# NPCX498S register map
File version: 1.0
Registers are 8-bit, read-write, reset 0x0 unless marked. A register's access mark holds for its fields unless they carry their own. Offsets are from the block's base; [hi:lo] are bit positions; {n}, {i} and the like mark numbered series; 'fields as' and 'values as' point back to an identical list.

## FLM
Base 0x400F8000
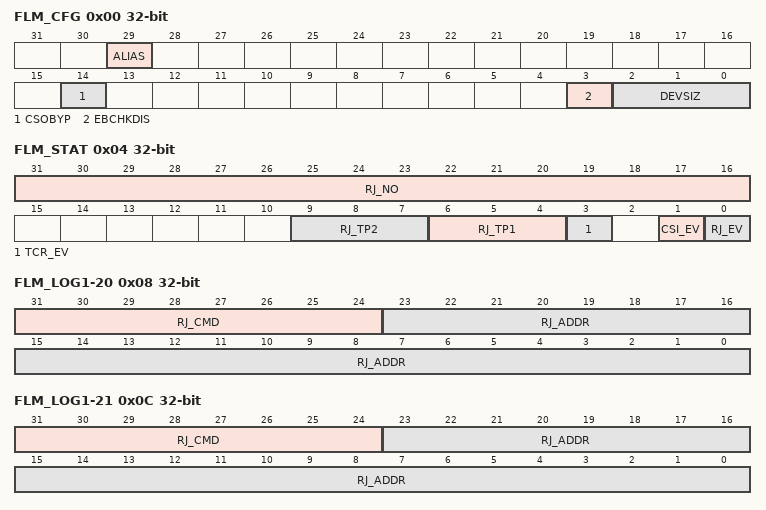
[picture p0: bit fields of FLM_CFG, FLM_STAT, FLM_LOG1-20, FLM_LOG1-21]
0x00 FLM_CFG 32-bit (reset mask 0xFF) — FLM Configuration Register (FLM_CFG)
  [29] ALIAS — Alias Flash Access Above Range
  [14] CSOBYP — FLM_CSIO Cut-Off Bypass
  [3] EBCHKDIS — Extra Bits Check Disable
  [2:0] DEVSIZ — Device Size
0x04 FLM_STAT 32-bit (reset mask 0xFF) — FLM Status Register (FLM_STAT)
  [31:16] RJ_NO — Rejection Number
  [9:7] RJ_TP2 — Rejection Type 2
  [6:4] RJ_TP1 — Rejection Type 1
  [3] TCR_EV — Transaction Counter Event
  [1] CSI_EV — Chip-Select Active Low Event
  [0] RJ_EV — Rejection Event
0x08 FLM_LOG1-20 32-bit (reset mask 0xFF) — FLM LOG Register 1-2 (FLM_LOG1-2)
  [31:24] RJ_CMD — Rejection Command Byte
  [23:0] RJ_ADDR — Rejection Address
0x0C FLM_LOG1-21 32-bit (reset mask 0xFF) — FLM LOG Register 1-2 (FLM_LOG1-2)
  fields as FLM_LOG1-20
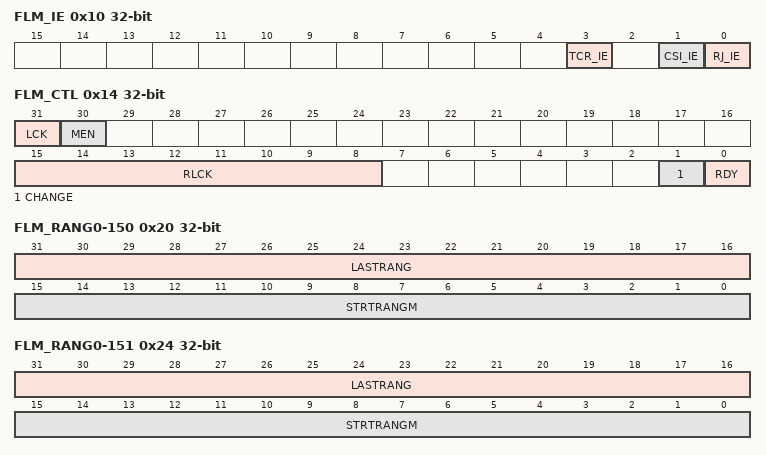
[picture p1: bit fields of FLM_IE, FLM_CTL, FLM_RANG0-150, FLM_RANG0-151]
0x10 FLM_IE 32-bit — FLM Interrupt Enable Register (FLM_IE)
  [3] TCR_IE — TCR_EV Interrupt Enable
  [1] CSI_IE — CSI_EV Interrupt Enable
  [0] RJ_IE — RJ_EV Interrupt Enable
0x14 FLM_CTL 32-bit (reset mask 0xFF) — FLM Control Register (FLM_CTL)
  [31] LCK — Lock
  [30] MEN — Module Enable
  [15:8] RLCK — Reversible Lock
  [1] CHANGE — Change and Update Configuration Parameters
  [0] RDY — Ready
0x20 FLM_RANG0-150 32-bit (reset mask 0xFF) — FLM Range Register 0-15 (FLM_RANG0-15)
  [31:16] LASTRANG — Range Last Address
  [15:0] STRTRANGM — Range Start Address
0x24 FLM_RANG0-151 32-bit (reset mask 0xFF) — FLM Range Register 0-15 (FLM_RANG0-15)
  fields as FLM_RANG0-150
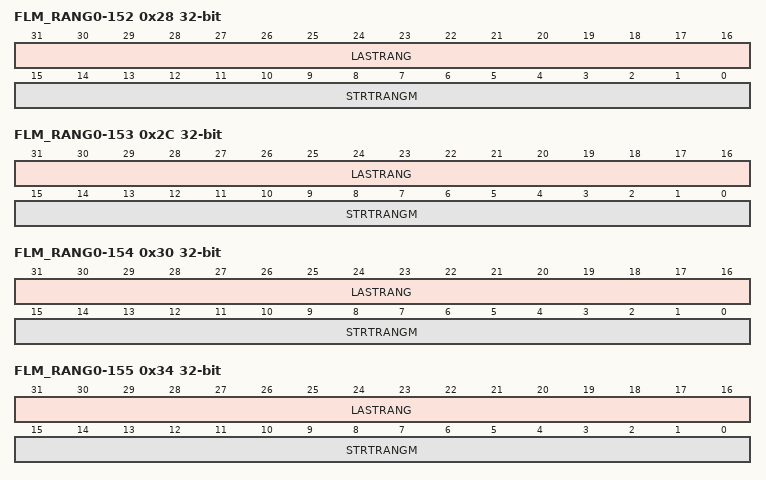
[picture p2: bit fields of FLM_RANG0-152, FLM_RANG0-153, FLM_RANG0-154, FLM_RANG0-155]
0x28 FLM_RANG0-152 32-bit (reset mask 0xFF) — FLM Range Register 0-15 (FLM_RANG0-15)
  fields as FLM_RANG0-150
0x2C FLM_RANG0-153 32-bit (reset mask 0xFF) — FLM Range Register 0-15 (FLM_RANG0-15)
  fields as FLM_RANG0-150
0x30 FLM_RANG0-154 32-bit (reset mask 0xFF) — FLM Range Register 0-15 (FLM_RANG0-15)
  fields as FLM_RANG0-150
0x34 FLM_RANG0-155 32-bit (reset mask 0xFF) — FLM Range Register 0-15 (FLM_RANG0-15)
  fields as FLM_RANG0-150
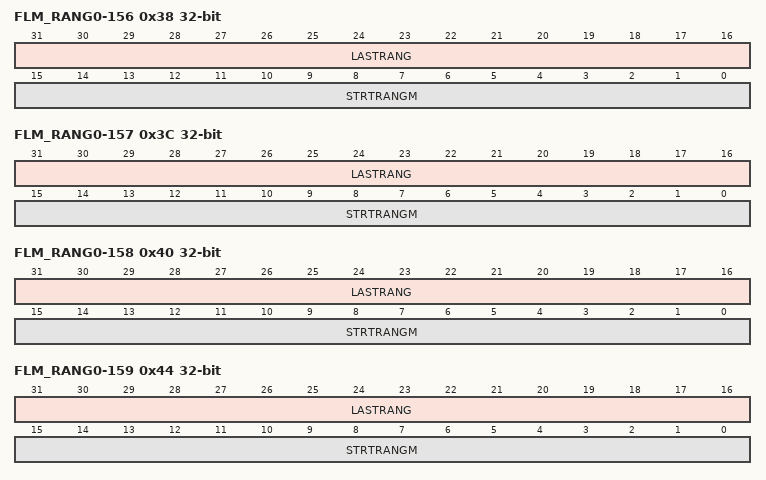
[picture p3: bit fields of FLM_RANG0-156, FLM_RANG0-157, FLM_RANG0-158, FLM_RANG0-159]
0x38 FLM_RANG0-156 32-bit (reset mask 0xFF) — FLM Range Register 0-15 (FLM_RANG0-15)
  fields as FLM_RANG0-150
0x3C FLM_RANG0-157 32-bit (reset mask 0xFF) — FLM Range Register 0-15 (FLM_RANG0-15)
  fields as FLM_RANG0-150
0x40 FLM_RANG0-158 32-bit (reset mask 0xFF) — FLM Range Register 0-15 (FLM_RANG0-15)
  fields as FLM_RANG0-150
0x44 FLM_RANG0-159 32-bit (reset mask 0xFF) — FLM Range Register 0-15 (FLM_RANG0-15)
  fields as FLM_RANG0-150
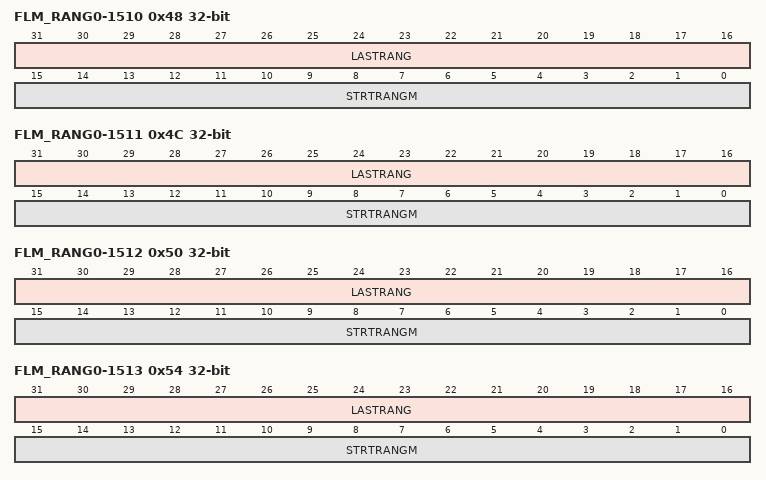
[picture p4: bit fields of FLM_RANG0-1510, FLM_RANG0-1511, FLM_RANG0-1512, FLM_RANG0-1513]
0x48 FLM_RANG0-1510 32-bit (reset mask 0xFF) — FLM Range Register 0-15 (FLM_RANG0-15)
  fields as FLM_RANG0-150
0x4C FLM_RANG0-1511 32-bit (reset mask 0xFF) — FLM Range Register 0-15 (FLM_RANG0-15)
  fields as FLM_RANG0-150
0x50 FLM_RANG0-1512 32-bit (reset mask 0xFF) — FLM Range Register 0-15 (FLM_RANG0-15)
  fields as FLM_RANG0-150
0x54 FLM_RANG0-1513 32-bit (reset mask 0xFF) — FLM Range Register 0-15 (FLM_RANG0-15)
  fields as FLM_RANG0-150
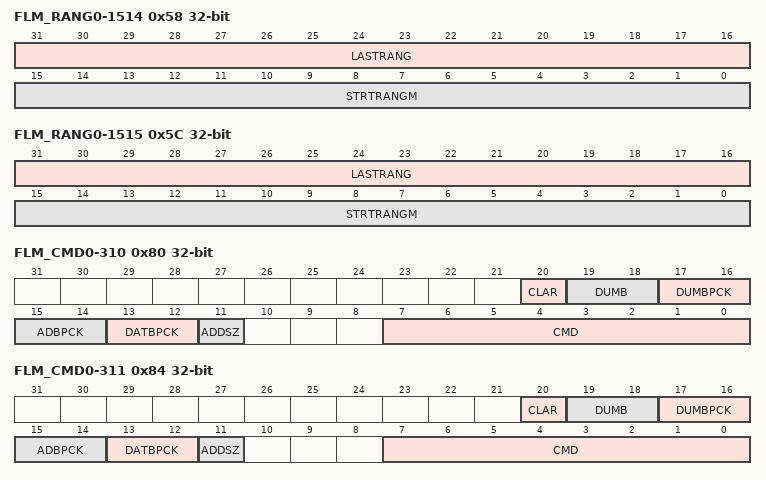
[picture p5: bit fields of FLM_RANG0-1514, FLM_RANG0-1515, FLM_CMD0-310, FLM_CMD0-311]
0x58 FLM_RANG0-1514 32-bit (reset mask 0xFF) — FLM Range Register 0-15 (FLM_RANG0-15)
  fields as FLM_RANG0-150
0x5C FLM_RANG0-1515 32-bit (reset mask 0xFF) — FLM Range Register 0-15 (FLM_RANG0-15)
  fields as FLM_RANG0-150
0x60 FLM_CMDEN 32-bit (reset mask 0xFF) — FLM Command Enable (FLM_CMDEN)
0x64 FLM_CMBEN 32-bit (reset mask 0xFF) — FLM Command Byte Enable (FLM_CMBEN)
0x80 FLM_CMD0-310 32-bit (reset mask 0xFF) — FLM Command Register 0-31 (FLM_CMD0-31)
  [20] CLAR — Command Limited Address Range
  [19:18] DUMB — Dummy Bytes
  [17:16] DUMBPCK — Dummy Bits Per Clock
  [15:14] ADBPCK — Address Bits Per Clock
  [13:12] DATBPCK — Data Bits Per Clock
  [11] ADDSZ — Address Size for Limiting Command
  [7:0] CMD — Command Byte
0x84 FLM_CMD0-311 32-bit (reset mask 0xFF) — FLM Command Register 0-31 (FLM_CMD0-31)
  fields as FLM_CMD0-310
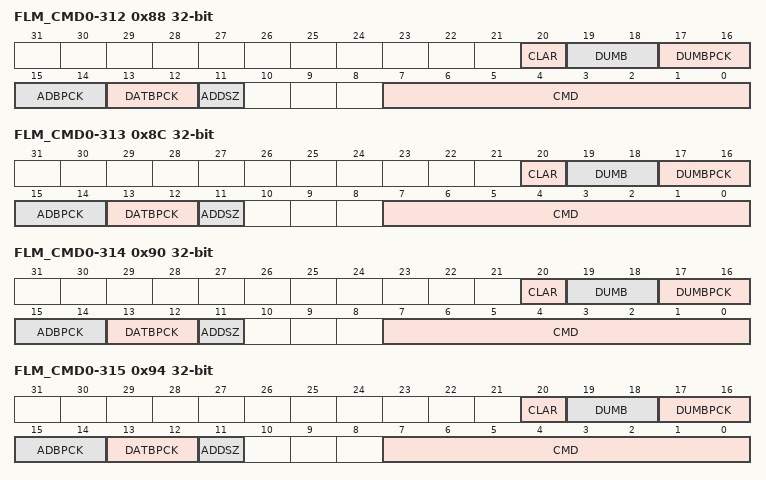
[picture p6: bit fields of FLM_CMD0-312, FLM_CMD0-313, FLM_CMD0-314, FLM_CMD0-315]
0x88 FLM_CMD0-312 32-bit (reset mask 0xFF) — FLM Command Register 0-31 (FLM_CMD0-31)
  fields as FLM_CMD0-310
0x8C FLM_CMD0-313 32-bit (reset mask 0xFF) — FLM Command Register 0-31 (FLM_CMD0-31)
  fields as FLM_CMD0-310
0x90 FLM_CMD0-314 32-bit (reset mask 0xFF) — FLM Command Register 0-31 (FLM_CMD0-31)
  fields as FLM_CMD0-310
0x94 FLM_CMD0-315 32-bit (reset mask 0xFF) — FLM Command Register 0-31 (FLM_CMD0-31)
  fields as FLM_CMD0-310
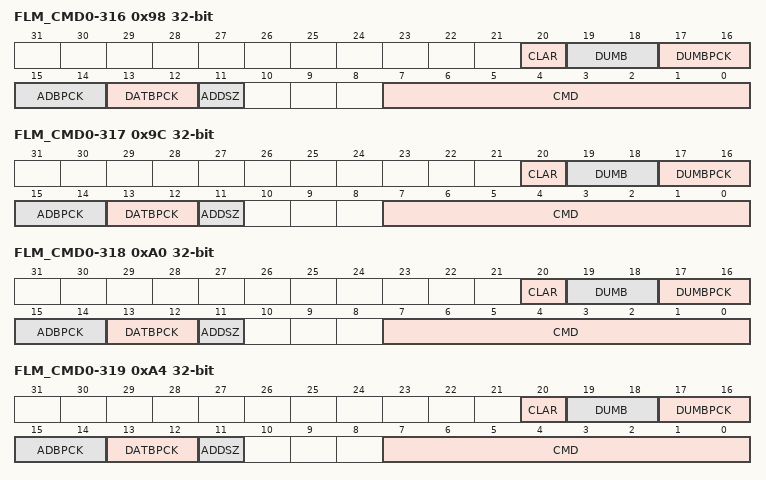
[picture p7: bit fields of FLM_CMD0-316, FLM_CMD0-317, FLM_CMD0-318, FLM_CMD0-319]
0x98 FLM_CMD0-316 32-bit (reset mask 0xFF) — FLM Command Register 0-31 (FLM_CMD0-31)
  fields as FLM_CMD0-310
0x9C FLM_CMD0-317 32-bit (reset mask 0xFF) — FLM Command Register 0-31 (FLM_CMD0-31)
  fields as FLM_CMD0-310
0xA0 FLM_CMD0-318 32-bit (reset mask 0xFF) — FLM Command Register 0-31 (FLM_CMD0-31)
  fields as FLM_CMD0-310
0xA4 FLM_CMD0-319 32-bit (reset mask 0xFF) — FLM Command Register 0-31 (FLM_CMD0-31)
  fields as FLM_CMD0-310
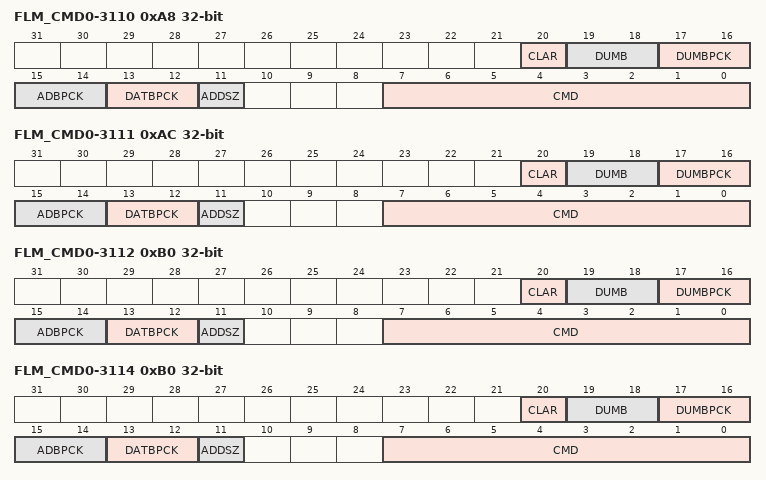
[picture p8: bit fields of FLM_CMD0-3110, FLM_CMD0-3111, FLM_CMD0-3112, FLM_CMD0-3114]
0xA8 FLM_CMD0-3110 32-bit (reset mask 0xFF) — FLM Command Register 0-31 (FLM_CMD0-31)
  fields as FLM_CMD0-310
0xAC FLM_CMD0-3111 32-bit (reset mask 0xFF) — FLM Command Register 0-31 (FLM_CMD0-31)
  fields as FLM_CMD0-310
0xB0 FLM_CMD0-3112 32-bit (reset mask 0xFF) — FLM Command Register 0-31 (FLM_CMD0-31)
  fields as FLM_CMD0-310
0xB0 FLM_CMD0-3114 32-bit (reset mask 0xFF) — FLM Command Register 0-31 (FLM_CMD0-31)
  fields as FLM_CMD0-310
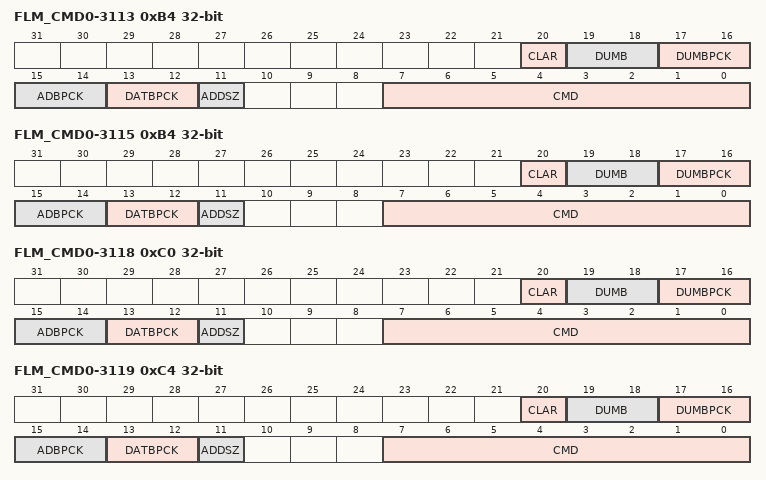
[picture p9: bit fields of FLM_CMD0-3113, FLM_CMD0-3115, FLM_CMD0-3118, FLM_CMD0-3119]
0xB4 FLM_CMD0-3113 32-bit (reset mask 0xFF) — FLM Command Register 0-31 (FLM_CMD0-31)
  fields as FLM_CMD0-310
0xB4 FLM_CMD0-3115 32-bit (reset mask 0xFF) — FLM Command Register 0-31 (FLM_CMD0-31)
  fields as FLM_CMD0-310
0xC0 FLM_CMD0-3118 32-bit (reset mask 0xFF) — FLM Command Register 0-31 (FLM_CMD0-31)
  fields as FLM_CMD0-310
0xC4 FLM_CMD0-3119 32-bit (reset mask 0xFF) — FLM Command Register 0-31 (FLM_CMD0-31)
  fields as FLM_CMD0-310
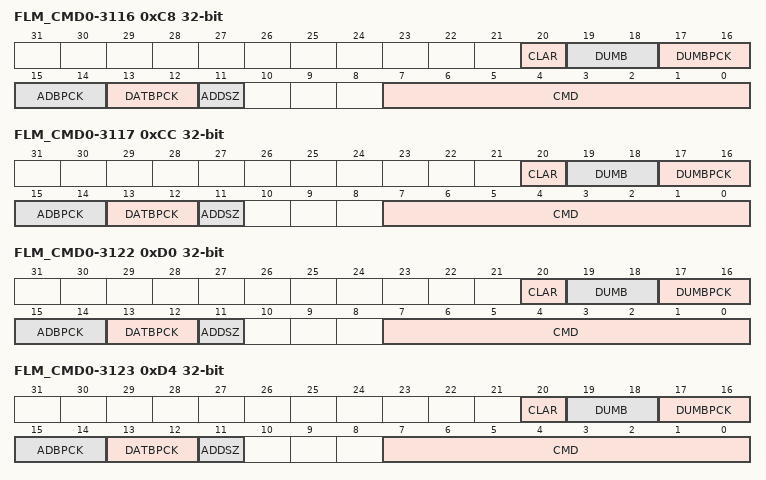
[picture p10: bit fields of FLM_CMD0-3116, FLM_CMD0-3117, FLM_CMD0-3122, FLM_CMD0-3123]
0xC8 FLM_CMD0-3116 32-bit (reset mask 0xFF) — FLM Command Register 0-31 (FLM_CMD0-31)
  fields as FLM_CMD0-310
0xCC FLM_CMD0-3117 32-bit (reset mask 0xFF) — FLM Command Register 0-31 (FLM_CMD0-31)
  fields as FLM_CMD0-310
0xD0 FLM_CMD0-3122 32-bit (reset mask 0xFF) — FLM Command Register 0-31 (FLM_CMD0-31)
  fields as FLM_CMD0-310
0xD4 FLM_CMD0-3123 32-bit (reset mask 0xFF) — FLM Command Register 0-31 (FLM_CMD0-31)
  fields as FLM_CMD0-310
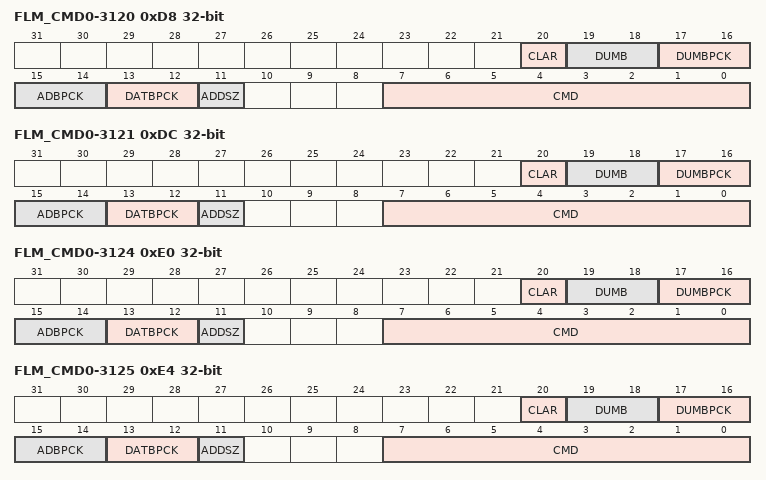
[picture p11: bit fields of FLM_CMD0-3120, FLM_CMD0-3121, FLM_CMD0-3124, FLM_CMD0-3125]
0xD8 FLM_CMD0-3120 32-bit (reset mask 0xFF) — FLM Command Register 0-31 (FLM_CMD0-31)
  fields as FLM_CMD0-310
0xDC FLM_CMD0-3121 32-bit (reset mask 0xFF) — FLM Command Register 0-31 (FLM_CMD0-31)
  fields as FLM_CMD0-310
0xE0 FLM_CMD0-3124 32-bit (reset mask 0xFF) — FLM Command Register 0-31 (FLM_CMD0-31)
  fields as FLM_CMD0-310
0xE4 FLM_CMD0-3125 32-bit (reset mask 0xFF) — FLM Command Register 0-31 (FLM_CMD0-31)
  fields as FLM_CMD0-310
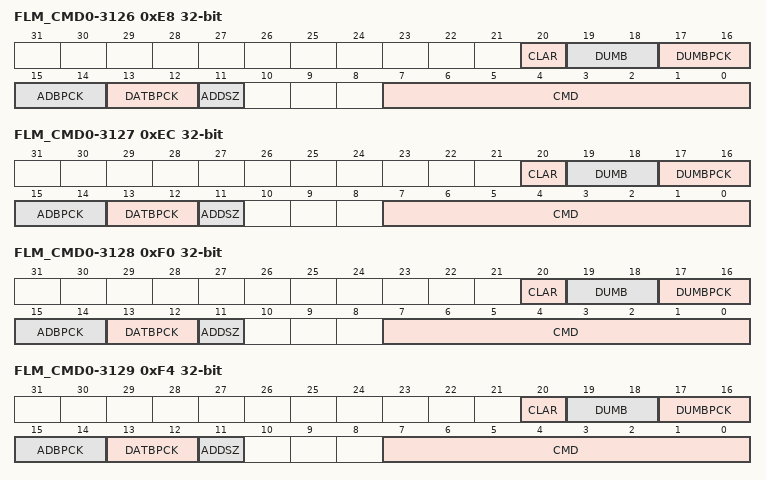
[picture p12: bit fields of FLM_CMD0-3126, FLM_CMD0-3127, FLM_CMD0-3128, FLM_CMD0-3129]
0xE8 FLM_CMD0-3126 32-bit (reset mask 0xFF) — FLM Command Register 0-31 (FLM_CMD0-31)
  fields as FLM_CMD0-310
0xEC FLM_CMD0-3127 32-bit (reset mask 0xFF) — FLM Command Register 0-31 (FLM_CMD0-31)
  fields as FLM_CMD0-310
0xF0 FLM_CMD0-3128 32-bit (reset mask 0xFF) — FLM Command Register 0-31 (FLM_CMD0-31)
  fields as FLM_CMD0-310
0xF4 FLM_CMD0-3129 32-bit (reset mask 0xFF) — FLM Command Register 0-31 (FLM_CMD0-31)
  fields as FLM_CMD0-310
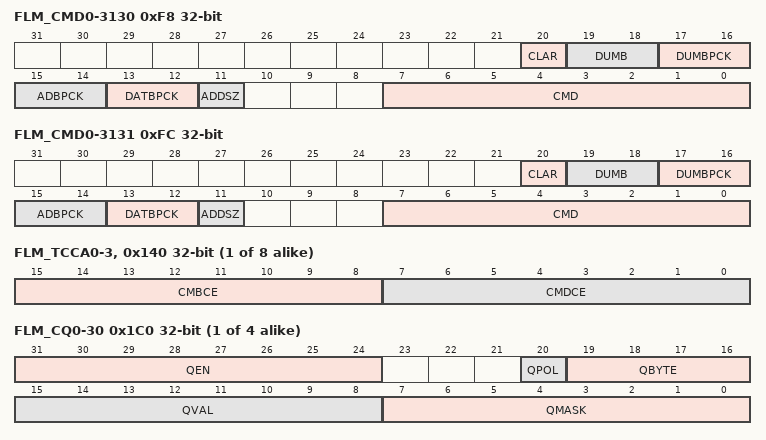
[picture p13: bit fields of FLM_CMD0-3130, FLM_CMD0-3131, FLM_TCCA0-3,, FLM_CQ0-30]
0xF8 FLM_CMD0-3130 32-bit (reset mask 0xFF) — FLM Command Register 0-31 (FLM_CMD0-31)
  fields as FLM_CMD0-310
0xFC FLM_CMD0-3131 32-bit (reset mask 0xFF) — FLM Command Register 0-31 (FLM_CMD0-31)
  fields as FLM_CMD0-310
{0x88+4i} FLM_TCRA0-3, FLM_TCRB0-{i} 32-bit (reset mask 0xFF) (i=30..37) — FLM Transaction Counter Read Register A0-A3, B0-B3 (FLM_TCRA0-3, FLM_TCRB0-3)
  [23:0] TCV — Transaction Counter Value
{0xC8+4i} FLM_TCCA0-3, FLM_TCCB0-{i} 32-bit (reset mask 0xFF) (i=30..37) — FLM Transaction Counter Control Register A0-A3, B0-B3 (FLM_TCCA0-3, FLM_TCCB0-3)
  [15:8] CMBCE — CMB Count Enable
  [7:0] CMDCE — CMD Count Enable
0x180 FLM_CMDEV 32-bit (reset mask 0xFF) — FLM CMD Event Register (FLM_CMDEV)
0x184 FLM_CMBEV 32-bit (reset mask 0xFF) — FLM CMB Event Register (FLM_CMBEV)
0x188 FLM_TCGC 32-bit — FLM Transaction Counter Global Control Register (FLM_TCGC)
  [0] TCCLR — Transaction Counters Clear
{0x148+4i} FLM_CQ0-{i} 32-bit (reset mask 0xFF) (i=30..33) — FLM Command Qualifier Register 0-3 (FLM_CQ0-3)
  [31:24] QEN — Qualifier Enable
  [20] QPOL — Qualifier Compare Polarity
  [19:16] QBYTE — Qualifier Compare Byte Index
  [15:8] QVAL — Qualifier Compare Value
  [7:0] QMASK — Qualifier Compare Mask
0x200 FLM_CMDARS0-310 32-bit (reset mask 0xFF) — FLM Command Address Range Select Register 0-31 (FLM_CMDARS0-31)
  [15:0] CARSEL — Command Address Range Select
0x204 FLM_CMDARS0-311 32-bit (reset mask 0xFF) — FLM Command Address Range Select Register 0-31 (FLM_CMDARS0-31)
  [15:0] CARSEL — Command Address Range Select
0x208 FLM_CMDARS0-312 32-bit (reset mask 0xFF) — FLM Command Address Range Select Register 0-31 (FLM_CMDARS0-31)
  [15:0] CARSEL — Command Address Range Select
0x20C FLM_CMDARS0-313 32-bit (reset mask 0xFF) — FLM Command Address Range Select Register 0-31 (FLM_CMDARS0-31)
  [15:0] CARSEL — Command Address Range Select
0x210 FLM_CMDARS0-314 32-bit (reset mask 0xFF) — FLM Command Address Range Select Register 0-31 (FLM_CMDARS0-31)
  [15:0] CARSEL — Command Address Range Select
0x214 FLM_CMDARS0-315 32-bit (reset mask 0xFF) — FLM Command Address Range Select Register 0-31 (FLM_CMDARS0-31)
  [15:0] CARSEL — Command Address Range Select
0x218 FLM_CMDARS0-316 32-bit (reset mask 0xFF) — FLM Command Address Range Select Register 0-31 (FLM_CMDARS0-31)
  [15:0] CARSEL — Command Address Range Select
0x21C FLM_CMDARS0-317 32-bit (reset mask 0xFF) — FLM Command Address Range Select Register 0-31 (FLM_CMDARS0-31)
  [15:0] CARSEL — Command Address Range Select
0x220 FLM_CMDARS0-318 32-bit (reset mask 0xFF) — FLM Command Address Range Select Register 0-31 (FLM_CMDARS0-31)
  [15:0] CARSEL — Command Address Range Select
0x224 FLM_CMDARS0-319 32-bit (reset mask 0xFF) — FLM Command Address Range Select Register 0-31 (FLM_CMDARS0-31)
  [15:0] CARSEL — Command Address Range Select
0x228 FLM_CMDARS0-3110 32-bit (reset mask 0xFF) — FLM Command Address Range Select Register 0-31 (FLM_CMDARS0-31)
  [15:0] CARSEL — Command Address Range Select
0x22C FLM_CMDARS0-3111 32-bit (reset mask 0xFF) — FLM Command Address Range Select Register 0-31 (FLM_CMDARS0-31)
  [15:0] CARSEL — Command Address Range Select
0x230 FLM_CMDARS0-3112 32-bit (reset mask 0xFF) — FLM Command Address Range Select Register 0-31 (FLM_CMDARS0-31)
  [15:0] CARSEL — Command Address Range Select
0x230 FLM_CMDARS0-3114 32-bit (reset mask 0xFF) — FLM Command Address Range Select Register 0-31 (FLM_CMDARS0-31)
  [15:0] CARSEL — Command Address Range Select
0x234 FLM_CMDARS0-3113 32-bit (reset mask 0xFF) — FLM Command Address Range Select Register 0-31 (FLM_CMDARS0-31)
  [15:0] CARSEL — Command Address Range Select
0x234 FLM_CMDARS0-3115 32-bit (reset mask 0xFF) — FLM Command Address Range Select Register 0-31 (FLM_CMDARS0-31)
  [15:0] CARSEL — Command Address Range Select
0x240 FLM_CMDARS0-3118 32-bit (reset mask 0xFF) — FLM Command Address Range Select Register 0-31 (FLM_CMDARS0-31)
  [15:0] CARSEL — Command Address Range Select
0x244 FLM_CMDARS0-3119 32-bit (reset mask 0xFF) — FLM Command Address Range Select Register 0-31 (FLM_CMDARS0-31)
  [15:0] CARSEL — Command Address Range Select
0x248 FLM_CMDARS0-3116 32-bit (reset mask 0xFF) — FLM Command Address Range Select Register 0-31 (FLM_CMDARS0-31)
  [15:0] CARSEL — Command Address Range Select
0x24C FLM_CMDARS0-3117 32-bit (reset mask 0xFF) — FLM Command Address Range Select Register 0-31 (FLM_CMDARS0-31)
  [15:0] CARSEL — Command Address Range Select
0x250 FLM_CMDARS0-3122 32-bit (reset mask 0xFF) — FLM Command Address Range Select Register 0-31 (FLM_CMDARS0-31)
  [15:0] CARSEL — Command Address Range Select
0x254 FLM_CMDARS0-3123 32-bit (reset mask 0xFF) — FLM Command Address Range Select Register 0-31 (FLM_CMDARS0-31)
  [15:0] CARSEL — Command Address Range Select
0x258 FLM_CMDARS0-3120 32-bit (reset mask 0xFF) — FLM Command Address Range Select Register 0-31 (FLM_CMDARS0-31)
  [15:0] CARSEL — Command Address Range Select
0x25C FLM_CMDARS0-3121 32-bit (reset mask 0xFF) — FLM Command Address Range Select Register 0-31 (FLM_CMDARS0-31)
  [15:0] CARSEL — Command Address Range Select
0x260 FLM_CMDARS0-3124 32-bit (reset mask 0xFF) — FLM Command Address Range Select Register 0-31 (FLM_CMDARS0-31)
  [15:0] CARSEL — Command Address Range Select
0x264 FLM_CMDARS0-3125 32-bit (reset mask 0xFF) — FLM Command Address Range Select Register 0-31 (FLM_CMDARS0-31)
  [15:0] CARSEL — Command Address Range Select
0x268 FLM_CMDARS0-3126 32-bit (reset mask 0xFF) — FLM Command Address Range Select Register 0-31 (FLM_CMDARS0-31)
  [15:0] CARSEL — Command Address Range Select
0x26C FLM_CMDARS0-3127 32-bit (reset mask 0xFF) — FLM Command Address Range Select Register 0-31 (FLM_CMDARS0-31)
  [15:0] CARSEL — Command Address Range Select
0x270 FLM_CMDARS0-3128 32-bit (reset mask 0xFF) — FLM Command Address Range Select Register 0-31 (FLM_CMDARS0-31)
  [15:0] CARSEL — Command Address Range Select
0x274 FLM_CMDARS0-3129 32-bit (reset mask 0xFF) — FLM Command Address Range Select Register 0-31 (FLM_CMDARS0-31)
  [15:0] CARSEL — Command Address Range Select
0x278 FLM_CMDARS0-3130 32-bit (reset mask 0xFF) — FLM Command Address Range Select Register 0-31 (FLM_CMDARS0-31)
  [15:0] CARSEL — Command Address Range Select
0x27C FLM_CMDARS0-3131 32-bit (reset mask 0xFF) — FLM Command Address Range Select Register 0-31 (FLM_CMDARS0-31)
  [15:0] CARSEL — Command Address Range Select
0x280 FLM_CMB0-310 32-bit — FLM Command Byte Register 0-31 (FLM_CMB0-31)
  [7:0] CMD — Command Byte
0x284 FLM_CMB0-311 32-bit — FLM Command Byte Register 0-31 (FLM_CMB0-31)
  [7:0] CMD — Command Byte
0x288 FLM_CMB0-312 32-bit — FLM Command Byte Register 0-31 (FLM_CMB0-31)
  [7:0] CMD — Command Byte
0x28C FLM_CMB0-313 32-bit — FLM Command Byte Register 0-31 (FLM_CMB0-31)
  [7:0] CMD — Command Byte
0x290 FLM_CMB0-314 32-bit — FLM Command Byte Register 0-31 (FLM_CMB0-31)
  [7:0] CMD — Command Byte
0x294 FLM_CMB0-315 32-bit — FLM Command Byte Register 0-31 (FLM_CMB0-31)
  [7:0] CMD — Command Byte
0x298 FLM_CMB0-316 32-bit — FLM Command Byte Register 0-31 (FLM_CMB0-31)
  [7:0] CMD — Command Byte
0x29C FLM_CMB0-317 32-bit — FLM Command Byte Register 0-31 (FLM_CMB0-31)
  [7:0] CMD — Command Byte
0x2A0 FLM_CMB0-318 32-bit — FLM Command Byte Register 0-31 (FLM_CMB0-31)
  [7:0] CMD — Command Byte
0x2A4 FLM_CMB0-319 32-bit — FLM Command Byte Register 0-31 (FLM_CMB0-31)
  [7:0] CMD — Command Byte
0x2A8 FLM_CMB0-3110 32-bit — FLM Command Byte Register 0-31 (FLM_CMB0-31)
  [7:0] CMD — Command Byte
0x2AC FLM_CMB0-3111 32-bit — FLM Command Byte Register 0-31 (FLM_CMB0-31)
  [7:0] CMD — Command Byte
0x2B0 FLM_CMB0-3112 32-bit — FLM Command Byte Register 0-31 (FLM_CMB0-31)
  [7:0] CMD — Command Byte
0x2B0 FLM_CMB0-3114 32-bit — FLM Command Byte Register 0-31 (FLM_CMB0-31)
  [7:0] CMD — Command Byte
0x2B4 FLM_CMB0-3113 32-bit — FLM Command Byte Register 0-31 (FLM_CMB0-31)
  [7:0] CMD — Command Byte
0x2B4 FLM_CMB0-3115 32-bit — FLM Command Byte Register 0-31 (FLM_CMB0-31)
  [7:0] CMD — Command Byte
0x2C0 FLM_CMB0-3118 32-bit — FLM Command Byte Register 0-31 (FLM_CMB0-31)
  [7:0] CMD — Command Byte
0x2C4 FLM_CMB0-3119 32-bit — FLM Command Byte Register 0-31 (FLM_CMB0-31)
  [7:0] CMD — Command Byte
0x2C8 FLM_CMB0-3116 32-bit — FLM Command Byte Register 0-31 (FLM_CMB0-31)
  [7:0] CMD — Command Byte
0x2CC FLM_CMB0-3117 32-bit — FLM Command Byte Register 0-31 (FLM_CMB0-31)
  [7:0] CMD — Command Byte
0x2D0 FLM_CMB0-3122 32-bit — FLM Command Byte Register 0-31 (FLM_CMB0-31)
  [7:0] CMD — Command Byte
0x2D4 FLM_CMB0-3123 32-bit — FLM Command Byte Register 0-31 (FLM_CMB0-31)
  [7:0] CMD — Command Byte
0x2D8 FLM_CMB0-3120 32-bit — FLM Command Byte Register 0-31 (FLM_CMB0-31)
  [7:0] CMD — Command Byte
0x2DC FLM_CMB0-3121 32-bit — FLM Command Byte Register 0-31 (FLM_CMB0-31)
  [7:0] CMD — Command Byte
0x2E0 FLM_CMB0-3124 32-bit — FLM Command Byte Register 0-31 (FLM_CMB0-31)
  [7:0] CMD — Command Byte
0x2E4 FLM_CMB0-3125 32-bit — FLM Command Byte Register 0-31 (FLM_CMB0-31)
  [7:0] CMD — Command Byte
0x2E8 FLM_CMB0-3126 32-bit — FLM Command Byte Register 0-31 (FLM_CMB0-31)
  [7:0] CMD — Command Byte
0x2EC FLM_CMB0-3127 32-bit — FLM Command Byte Register 0-31 (FLM_CMB0-31)
  [7:0] CMD — Command Byte
0x2F0 FLM_CMB0-3128 32-bit — FLM Command Byte Register 0-31 (FLM_CMB0-31)
  [7:0] CMD — Command Byte
0x2F4 FLM_CMB0-3129 32-bit — FLM Command Byte Register 0-31 (FLM_CMB0-31)
  [7:0] CMD — Command Byte
0x2F8 FLM_CMB0-3130 32-bit — FLM Command Byte Register 0-31 (FLM_CMB0-31)
  [7:0] CMD — Command Byte
0x2FC FLM_CMB0-3131 32-bit — FLM Command Byte Register 0-31 (FLM_CMB0-31)
  [7:0] CMD — Command Byte
